# STM32WBA25xx register map
File version: 1.0
Registers are 32-bit, read-write, reset 0x0 unless marked. A register's access mark holds for its fields unless they carry their own. Offsets are from the block's base; lines under a group give offsets from that group; [hi:lo] are bit positions; {n}, {i} and the like mark numbered series; 'fields as' and 'values as' point back to an identical list; <NAME> marks a mode.

## Memory map
0x0BF8CD40 RSSLIB_PFUNC — RSSLib function pointer structure
0x40000000 TIM2 — TIM
0x40003000 IWDG
0x40005400 I2C1 — Inter-integrated Circuit Interface
0x40009400 LPTIM2 — LPTIMER
0x40013800 USART1 — Universal Synchronous Asynchronous Receiver Transmitter
0x40014400 TIM16 — TIM
0x40014800 TIM17 — TIM
0x40015400 SAI1 — Serial Audio Interface
0x40016000 USB_DRD_FS — Universal Serial Bus Full Speed Dual Role Device
0x40016400 USB_DRD_PMA_BUFF — Universal Serial Bus PacketMemoryArea Buffer Descriptor Table
0x40020000 LPDMA1 — DMA Controller
0x40022000 FLASH — FLASH Registers
0x40023000 CRC — CRC calculation unit
0x40026000 RAMCFG
0x40030400 ICACHE — Instruction Cache
0x40032400 GTZC_TZSC — Global TrustZone Controller
0x40032C00 GTZC_MPCBB1
0x40033000 GTZC_MPCBB2
0x42020000 GPIOA — General Purpose I/O
0x42020400 GPIOB — General Purpose I/O
0x42020800 GPIOC — General Purpose I/O
0x42021C00 GPIOH — General Purpose I/O
0x420C0000 AES — AES hardware accelerator
0x420C0400 HASH
0x420C0800 RNG
0x420C2000 PKA
0x420C5000 OTFDEC1
0x420CF000 DLYB1
0x420D1400 XSPI1 — XSPI register block
0x46000400 SYSCFG — System configuration controller
0x46002000 SPI3 — SPI
0x46002400 LPUART1 — Universal Synchronous Asynchronous Receiver Transmitter
0x46002800 I2C3 — Inter-integrated Circuit Interface
0x46004400 LPTIM1 — LPTIMER
0x46007800 RTC — Real-Time Clock
0x46007C00 TAMP — Tamper and backup registers
0x46020800 PWR — Power Control
0x46020C00 RCC — Reset and Clock Control
0x46021000 ADC4 — Analog to Digital Converter (ADC)
0x46022000 EXTI — Asynch Interrupt/Event Controller (EXTI)
0x48038000 PTACONV
0xE0044000 DBGMCU — Debug MCU

## Interrupts
2 RTC — RTC non-secure interrupt
3 RTC_S (RTC) — RTC secure interrupt
4 TAMP — Tamper global interrupt
5 RAMCFG — RAMCFG global interrupt
6 FLASH — FLASH non-secure global interrupt
7 FLASH_S (FLASH) — FLASH secure global interrupt
9 RCC — RCC non secure global interrupt
10 RCC_S (RCC) — RCC secure global interrupt
{n+11} EXTI{n} (EXTI) (n=1..15) — EXTI Line{n} interrupt
27 IWDG — IWDG global interrupt
{n+28} LPDMA1_Channel{n} (LPDMA1) (n=0..7) — LPDMA1 Channel {n} global interrupt
36 OTFDEC1 — OTFDEC1 global interrupt
40 TIM2 — TIM2 global interrupt
41 I2C1_EV (I2C1) — I2C1 Event interrupt
42 I2C1_ER (I2C1) — I2C1 Error interrupt
43 USART1 — USART1 global interrupt
44 LPUART1 — LPUART1 global interrupt
45 LPTIM1 — LPTIM1 global interrupt
46 LPTIM2 — LPTIM2 global interrupt
47 TIM16 — TIM16 global interrupt
48 TIM17 — TIM17 global interrupt
49 I2C3_EV (I2C3) — I2C3 Event interrupt
50 I2C3_ER (I2C3) — I2C3 Error interrupt
51 SAI1 — Serial Audio Interface 1 global interrupt
52 AES — AES global interrupt
53 RNG — RNG global interrupt
55 HASH — HASH global interrupt
56 PKA — PKA global interrupt
57 SPI3 — SPI3 global interrupt
58 ICACHE — Instruction cache global interrupt
59 ADC4 — ADC4 global interrupt
63 RCC_AUDIOSYNC (RCC) — RCC audio synchronization interrupt
64 USB_DRD_FS — USB Dual Role device global interrupt
65 XSPI1 — XSPI1 global interrupt

## RSSLIB_PFUNC — RSSLib function pointer structure
Base 0x0BF8CD40
0x28 CloseExitHDP ro — RSSLIB Close and exit HDP
0x2C CloseExitHDPExt ro — RSSLIB Close and exit HDP extension

## IWDG
Base 0x40003000
0x00 KR — IWDG Key register
  [15:0] KEY — Key value (write only, read 0000h)
0x04 PR — IWDG Prescaler register
  [3:0] PR — PR[3:0] (Prescaler divider)
0x08 RLR — IWDG Reload register
  [11:0] RL — Watchdog counter reload value
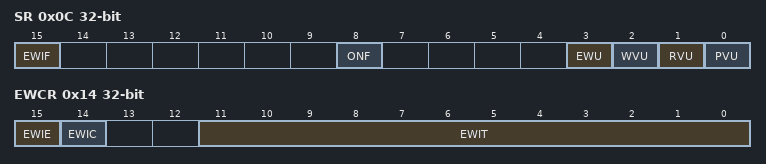
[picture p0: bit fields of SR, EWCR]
0x0C SR — IWDG Status register
  [15] EWIF — Watchdog early interrupt flag
  [8] ONF — Watchdog enable status bit
  [3] EWU — Watchdog interrupt comparator value update
  [2] WVU — Watchdog counter window value update
  [1] RVU — Watchdog counter reload value update
  [0] PVU — Watchdog prescaler value update
0x10 WINR — IWDG Window register
  [11:0] WIN — Watchdog counter window value
0x14 EWCR — IWDG Early Wakeup register
  [15] EWIE — Watchdog early wakeup comparator value
  [14] EWIC — Watchdog early wakeup comparator value
  [11:0] EWIT — Watchdog early wakeup comparator value
